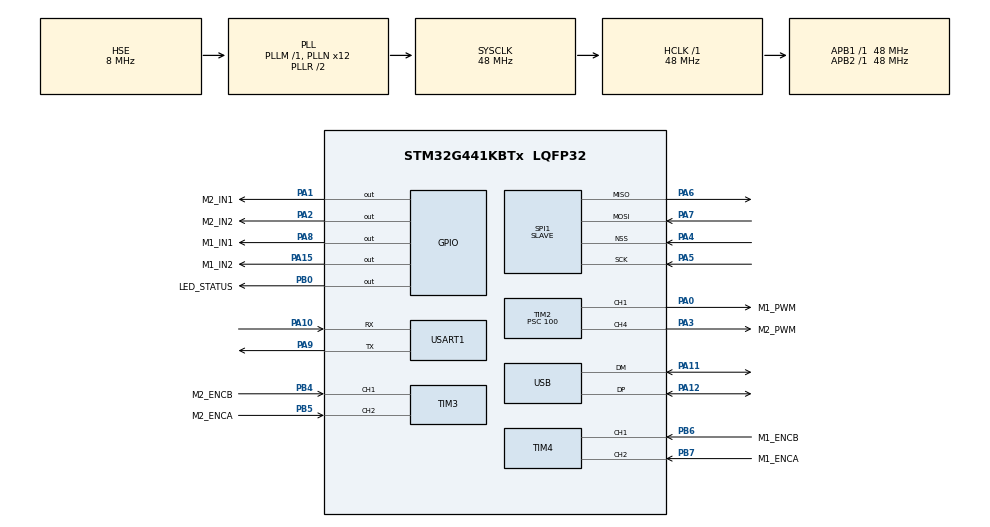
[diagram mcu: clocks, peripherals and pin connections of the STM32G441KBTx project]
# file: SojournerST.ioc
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FREERTOS.Tasks01=defaultTask,24,128,StartDefaultTask,Default,NULL,Dynamic,NULL,NULL
FREERTOS.configUSE_NEWLIB_REENTRANT=1
Mcu.Family=STM32G4
Mcu.Name=STM32G441KBTx
Mcu.Package=LQFP32
NVIC.PriorityGroup=NVIC_PRIORITYGROUP_4
NVIC.RCC_IRQn=true\:5\:0\:false\:false\:true\:true\:true\:false
NVIC.TIM6_DAC_IRQn=true\:15\:0\:false\:false\:true\:false\:false\:true
NVIC.TimeBase=TIM6_DAC_IRQn
NVIC.TimeBaseIP=TIM6
NVIC.USART1_IRQn=true\:5\:0\:false\:false\:true\:true\:true\:true
NVIC.USB_LP_IRQn=true\:5\:0\:false\:false\:true\:true\:false\:true
PA0.GPIO_Label=M1_PWM
PA0.Signal=S_TIM2_CH1
PA1.GPIO_Label=M2_IN1
PA1.Signal=GPIO_Output
PA10.Mode=Asynchronous
PA10.Signal=USART1_RX
PA11.Mode=Device
PA11.Signal=USB_DM
PA12.Mode=Device
PA12.Signal=USB_DP
PA13.Mode=Trace_Asynchronous_SW
PA13.Signal=SYS_JTMS-SWDIO
PA14.Mode=Trace_Asynchronous_SW
PA14.Signal=SYS_JTCK-SWCLK
PA15.GPIO_Label=M1_IN2
PA15.Signal=GPIO_Output
PA2.GPIO_Label=M2_IN2
PA2.Signal=GPIO_Output
PA3.GPIO_Label=M2_PWM
PA3.Signal=S_TIM2_CH4
PA4.Mode=NSS_Signal_Hard_Input
PA4.Signal=SPI1_NSS
PA5.Mode=Full_Duplex_Slave
PA5.Signal=SPI1_SCK
PA6.Mode=Full_Duplex_Slave
PA6.Signal=SPI1_MISO
PA7.Mode=Full_Duplex_Slave
PA7.Signal=SPI1_MOSI
PA8.GPIO_Label=M1_IN1
PA8.Signal=GPIO_Output
PA9.Mode=Asynchronous
PA9.Signal=USART1_TX
PB0.GPIO_Label=LED_STATUS
PB0.Signal=GPIO_Output
PB3.Mode=Trace_Asynchronous_SW
PB3.Signal=SYS_JTDO-SWO
PB4.GPIO_Label=M2_ENCB
PB4.Signal=S_TIM3_CH1
PB5.GPIO_Label=M2_ENCA
PB5.Signal=S_TIM3_CH2
PB6.GPIO_Label=M1_ENCB
PB6.Signal=S_TIM4_CH1
PB7.GPIO_Label=M1_ENCA
PB7.Signal=S_TIM4_CH2
PF0-OSC_IN.Mode=HSE-External-Oscillator
PF0-OSC_IN.Signal=RCC_OSC_IN
PF1-OSC_OUT.Mode=HSE-External-Oscillator
PF1-OSC_OUT.Signal=RCC_OSC_OUT
ProjectManager.HeapSize=0x200
ProjectManager.StackSize=0x400
ProjectManager.TargetToolchain=STM32CubeIDE
RCC.ADC12Freq_Value=48000000
RCC.AHBFreq_Value=48000000
RCC.APB1Freq_Value=48000000
RCC.APB1TimFreq_Value=48000000
RCC.APB2Freq_Value=48000000
RCC.APB2TimFreq_Value=48000000
RCC.CortexFreq_Value=48000000
RCC.EXTERNAL_CLOCK_VALUE=12288000
RCC.HCLKFreq_Value=48000000
RCC.HSE_VALUE=8000000
RCC.HSI48_VALUE=48000000
RCC.HSI_VALUE=16000000
RCC.LSE_VALUE=32768
RCC.PLLN=12
RCC.PLLSourceVirtual=RCC_PLLSOURCE_HSE
RCC.SYSCLKFreq_VALUE=48000000
RCC.SYSCLKSource=RCC_SYSCLKSOURCE_PLLCLK
RCC.USBFreq_Value=48000000
RCC.VCOOutputFreq_Value=96000000
SH.S_TIM2_CH1.0=TIM2_CH1,PWM Generation1 CH1
SH.S_TIM2_CH4.0=TIM2_CH4,PWM Generation4 CH4
SH.S_TIM3_CH1.0=TIM3_CH1,Encoder_Interface
SH.S_TIM3_CH2.0=TIM3_CH2,Encoder_Interface
SH.S_TIM4_CH1.0=TIM4_CH1,Encoder_Interface
SH.S_TIM4_CH2.0=TIM4_CH2,Encoder_Interface
SPI1.Direction=SPI_DIRECTION_2LINES
SPI1.Mode=SPI_MODE_SLAVE
SPI1.VirtualNSS=VM_NSSHARD
SPI1.VirtualType=VM_SLAVE
TIM2.Channel-PWM\ Generation1\ CH1=TIM_CHANNEL_1
TIM2.Channel-PWM\ Generation4\ CH4=TIM_CHANNEL_4
TIM2.PeriodNoDither=256
TIM2.Prescaler=100
USART1.VirtualMode-Asynchronous=VM_ASYNC
USB_DEVICE.CLASS_NAME_FS=CDC
USB_DEVICE.VirtualMode=Cdc
USB_DEVICE.VirtualModeFS=Cdc_FS
VP_FREERTOS_VS_CMSIS_V2.Mode=CMSIS_V2
VP_SYS_VS_DBSignals.Mode=DisableDeadBatterySignals
VP_SYS_VS_tim6.Mode=TIM6
VP_TIM2_VS_ClockSourceINT.Mode=Internal
VP_USB_DEVICE_VS_USB_DEVICE_CDC_FS.Mode=CDC_FS
board=custom

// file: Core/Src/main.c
/* USER CODE BEGIN Header */
/**
  ******************************************************************************
  * @file           : main.c
  * @brief          : Main program body
  ******************************************************************************
  * @attention
  *
  * <h2><center>&copy; Copyright (c) 2021 STMicroelectronics.
  * All rights reserved.</center></h2>
  *
  * This software component is licensed by ST under Ultimate Liberty license
  * SLA0044, the "License"; You may not use this file except in compliance with
  * the License. You may obtain a copy of the License at:
  *                             www.st.com/SLA0044
  *
  ******************************************************************************
  */
/* USER CODE END Header */
#include "main.h"
#include "cmsis_os.h"
#include "spi.h"
#include "tim.h"
#include "usart.h"
#include "usb_device.h"
#include "gpio.h"

/* USER CODE BEGIN Includes */
#include "cpp_bridge.h"
/* USER CODE END Includes */

void SystemClock_Config(void);
void MX_FREERTOS_Init(void);

/* USER CODE BEGIN 0 */
int main(){
	uwTickPrio = TICK_INT_PRIORITY;
	SystemClock_Config();
	HAL_Init();

	/* Configure the system clock */

	/* Initialize all configured peripherals */
	MX_GPIO_Init();
	MX_SPI1_Init();
	MX_TIM2_Init();
	MX_TIM3_Init();
	MX_TIM4_Init();
	MX_USART1_UART_Init();
	MX_USB_Device_Init();

	entrypoint();
  /* We should never get here as control is now taken by the scheduler */
  /* Infinite loop */
  while(1){
  }

}
/* USER CODE END 0 */

void SystemClock_Config(void)
{
  RCC_OscInitTypeDef RCC_OscInitStruct = {0};
  RCC_ClkInitTypeDef RCC_ClkInitStruct = {0};
  RCC_PeriphCLKInitTypeDef PeriphClkInit = {0};

  /** Configure the main internal regulator output voltage
  */
  HAL_PWREx_ControlVoltageScaling(PWR_REGULATOR_VOLTAGE_SCALE1);
  /** Initializes the RCC Oscillators according to the specified parameters
  * in the RCC_OscInitTypeDef structure.
  */
  RCC_OscInitStruct.OscillatorType = RCC_OSCILLATORTYPE_HSE;
  RCC_OscInitStruct.HSEState = RCC_HSE_ON;
  RCC_OscInitStruct.PLL.PLLState = RCC_PLL_ON;
  RCC_OscInitStruct.PLL.PLLSource = RCC_PLLSOURCE_HSE;
  RCC_OscInitStruct.PLL.PLLM = RCC_PLLM_DIV1;
  RCC_OscInitStruct.PLL.PLLN = 12;
  RCC_OscInitStruct.PLL.PLLP = RCC_PLLP_DIV2;
  RCC_OscInitStruct.PLL.PLLQ = RCC_PLLQ_DIV2;
  RCC_OscInitStruct.PLL.PLLR = RCC_PLLR_DIV2;
  if (HAL_RCC_OscConfig(&RCC_OscInitStruct) != HAL_OK)
  {
    Error_Handler();
  }
  /** Initializes the CPU, AHB and APB buses clocks
  */
  RCC_ClkInitStruct.ClockType = RCC_CLOCKTYPE_HCLK|RCC_CLOCKTYPE_SYSCLK
                              |RCC_CLOCKTYPE_PCLK1|RCC_CLOCKTYPE_PCLK2;
  RCC_ClkInitStruct.SYSCLKSource = RCC_SYSCLKSOURCE_PLLCLK;
  RCC_ClkInitStruct.AHBCLKDivider = RCC_SYSCLK_DIV1;
  RCC_ClkInitStruct.APB1CLKDivider = RCC_HCLK_DIV1;
  RCC_ClkInitStruct.APB2CLKDivider = RCC_HCLK_DIV1;

  if (HAL_RCC_ClockConfig(&RCC_ClkInitStruct, FLASH_LATENCY_1) != HAL_OK)
  {
    Error_Handler();
  }
  /** Initializes the peripherals clocks
  */
  PeriphClkInit.PeriphClockSelection = RCC_PERIPHCLK_USART1|RCC_PERIPHCLK_USB;
  PeriphClkInit.Usart1ClockSelection = RCC_USART1CLKSOURCE_PCLK2;
  PeriphClkInit.UsbClockSelection = RCC_USBCLKSOURCE_PLL;
  if (HAL_RCCEx_PeriphCLKConfig(&PeriphClkInit) != HAL_OK)
  {
    Error_Handler();
  }
}

void HAL_TIM_PeriodElapsedCallback(TIM_HandleTypeDef *htim)
{
  if (htim->Instance == TIM6) {
    HAL_IncTick();
  }
}

void Error_Handler(void)
{
  __disable_irq();
  while (1)
  {
  }
}

/************************ (C) COPYRIGHT STMicroelectronics *****END OF FILE****/
